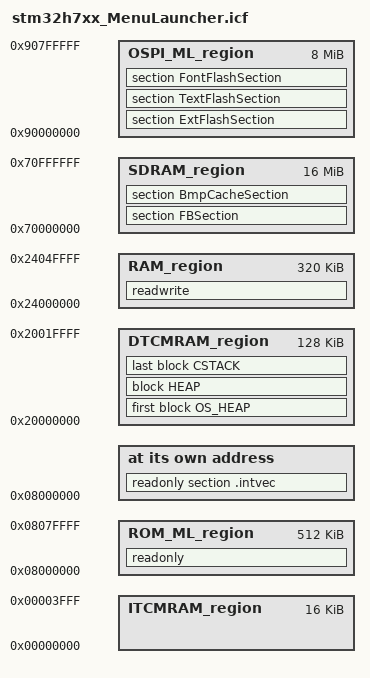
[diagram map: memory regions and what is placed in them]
/*###ICF### Section handled by ICF editor, don't touch! ****/
/*-Editor annotation file-*/
/* IcfEditorFile="$TOOLKIT_DIR$\config\ide\IcfEditor\cortex_v1_0.xml" */
/*-Specials-*/
define symbol __ICFEDIT_intvec_start__ = 0x08000000;
/*-Memory Regions-*/
define symbol __ICFEDIT_region_ROM_ML_start__   = 0x08000000;
define symbol __ICFEDIT_region_ROM_ML_end__     = 0x0807FFFF; /* 512 Kbytes for MenuLauncher */

/*-Internal RAM Memory Regions-*/
define symbol __ICFEDIT_region_ITCMRAM_start__    = 0x00000000;
define symbol __ICFEDIT_region_ITCMRAM_end__      = 0x00003FFF; /*   16 Kbytes */
define symbol __ICFEDIT_region_DTCMRAM_start__    = 0x20000000;
define symbol __ICFEDIT_region_DTCMRAM_end__      = 0x2001FFFF; /*  128 Kbytes */
define symbol __ICFEDIT_region_RAM_start__        = 0x24000000;
define symbol __ICFEDIT_region_RAM_end__          = 0x2404FFFF; /*  320 Kbytes */

/*-External RAM Memory Regions-*/
define symbol __ICFEDIT_region_SDRAM_start__      = 0x70000000; /*    8 Mbytes */
define symbol __ICFEDIT_region_SDRAM_end__        = 0x70FFFFFF;

/*-Quad-SPI Memory Regions-*/
define symbol __ICFEDIT_region_OSPI_ML_start__    = 0x90000000;
define symbol __ICFEDIT_region_OSPI_ML_end__      = 0x907FFFFF; /* 8 Mbytes */

/*-Sizes-*/
define symbol __ICFEDIT_size_cstack__ = 0x4000;  /* 16 Kb */
define symbol __ICFEDIT_size_heap__   = 0x4000;  /* 16 Kb */
/**** End of ICF editor section. ###ICF###*/

define memory mem with size = 4G;
define region ROM_ML_region   = mem:[from __ICFEDIT_region_ROM_ML_start__   to __ICFEDIT_region_ROM_ML_end__];

define region ITCMRAM_region    = mem:[from __ICFEDIT_region_ITCMRAM_start__    to __ICFEDIT_region_ITCMRAM_end__];
define region DTCMRAM_region    = mem:[from __ICFEDIT_region_DTCMRAM_start__    to __ICFEDIT_region_DTCMRAM_end__];
define region RAM_region        = mem:[from __ICFEDIT_region_RAM_start__        to __ICFEDIT_region_RAM_end__];
define region SDRAM_region      = mem:[from __ICFEDIT_region_SDRAM_start__      to __ICFEDIT_region_SDRAM_end__];

define region OSPI_ML_region  = mem:[from __ICFEDIT_region_OSPI_ML_start__  to __ICFEDIT_region_OSPI_ML_end__];

define block CSTACK     with alignment = 8, size = __ICFEDIT_size_cstack__    { };
define block HEAP       with alignment = 8, size = __ICFEDIT_size_heap__      { };
define block OS_HEAP    with alignment = 8 { section heap_mem };

/*-Third Party Demonstration Headers-*/
define symbol __thp_int_header_start__ = __ICFEDIT_region_ROM_ML_start__ + 0x1000;
define symbol __thp_ext_header_start__ = __ICFEDIT_region_OSPI_ML_start__;

initialize by copy { readwrite };
do not initialize  { section .noinit, section FBSection, section BmpCacheSection };

place at address mem:__ICFEDIT_intvec_start__ { readonly section .intvec };

/*-Third Party headers Memory Placement-*/

/* Other sections placement */
place in DTCMRAM_region     { first block OS_HEAP, block HEAP, last block CSTACK };
place in RAM_region         { readwrite };
place in SDRAM_region       { section FBSection, section BmpCacheSection };
place in ROM_ML_region      { readonly };
place in OSPI_ML_region     { section ExtFlashSection
                            , section TextFlashSection
                            , section FontFlashSection };
